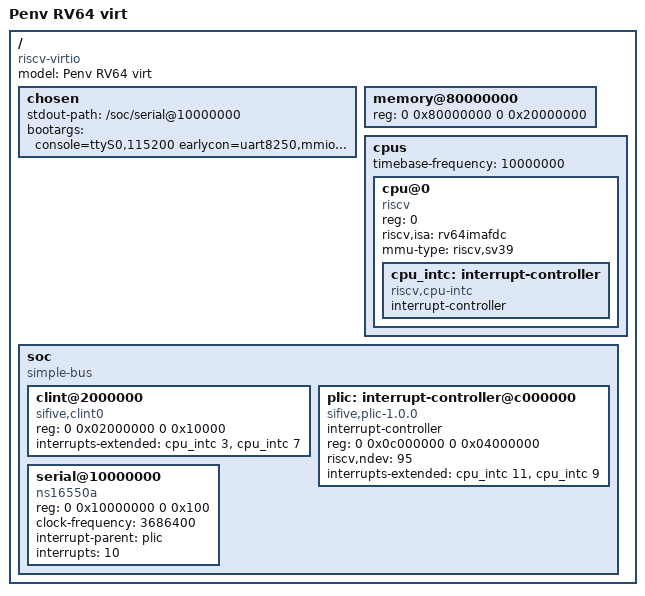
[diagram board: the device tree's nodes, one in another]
/dts-v1/;

/ {
    #address-cells = <2>;
    #size-cells = <2>;
    compatible = "riscv-virtio";
    model = "Penv RV64 virt";

    chosen {
        stdout-path = "/soc/serial@10000000";
        bootargs = "console=ttyS0,115200 earlycon=uart8250,mmio,0x10000000";
        /* Set the bounds from the initramfs length before booting. */
    };

    memory@80000000 {
        device_type = "memory";
        reg = <0 0x80000000 0 0x20000000>;
    };

    cpus {
        #address-cells = <1>;
        #size-cells = <0>;
        timebase-frequency = <10000000>;

        cpu@0 {
            device_type = "cpu";
            reg = <0>;
            status = "okay";
            compatible = "riscv";
            riscv,isa = "rv64imafdc";
            mmu-type = "riscv,sv39";

            cpu_intc: interrupt-controller {
                #address-cells = <0>;
                #interrupt-cells = <1>;
                interrupt-controller;
                compatible = "riscv,cpu-intc";
            };
        };
    };

    soc {
        #address-cells = <2>;
        #size-cells = <2>;
        compatible = "simple-bus";
        ranges;

        clint@2000000 {
            compatible = "sifive,clint0", "riscv,clint0";
            reg = <0 0x02000000 0 0x10000>;
            interrupts-extended = <&cpu_intc 3 &cpu_intc 7>;
        };

        plic: interrupt-controller@c000000 {
            #address-cells = <0>;
            #interrupt-cells = <1>;
            interrupt-controller;
            compatible = "sifive,plic-1.0.0", "riscv,plic0";
            reg = <0 0x0c000000 0 0x04000000>;
            riscv,ndev = <95>;
            interrupts-extended = <&cpu_intc 11 &cpu_intc 9>;
        };

        serial@10000000 {
            compatible = "ns16550a";
            reg = <0 0x10000000 0 0x100>;
            clock-frequency = <3686400>;
            interrupt-parent = <&plic>;
            interrupts = <10>;
        };
    };
};
